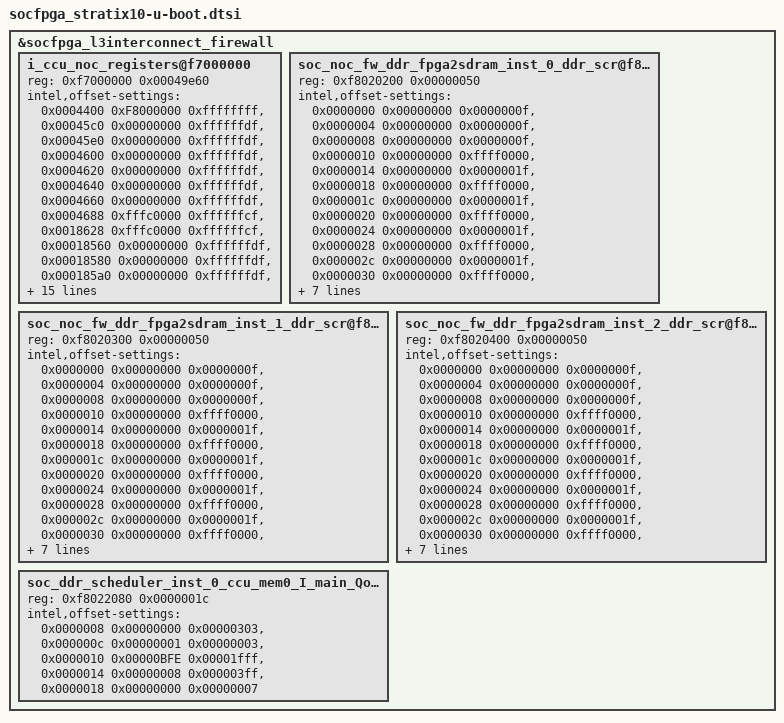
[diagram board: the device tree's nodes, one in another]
// SPDX-License-Identifier: GPL-2.0+
/*
 * U-Boot additions
 *
 * Copyright (C) 2020 Intel Corporation <www.intel.com>
 */

#include "socfpga_soc64_u-boot.dtsi"
#include "socfpga_soc64_fit-u-boot.dtsi"

&socfpga_l3interconnect_firewall {
	i_ccu_noc_registers@f7000000 {
		reg = <0xf7000000 0x00049e60>;
		intel,offset-settings =
			/* Enable access to DDR reg from CPU */
			<0x0004400 0xF8000000 0xffffffff>,

			/* Enable access to DDR region from CPU */
			<0x00045c0 0x00000000 0xffffffdf>,
			<0x00045e0 0x00000000 0xffffffdf>,
			<0x0004600 0x00000000 0xffffffdf>,
			<0x0004620 0x00000000 0xffffffdf>,
			<0x0004640 0x00000000 0xffffffdf>,
			<0x0004660 0x00000000 0xffffffdf>,

			/* Disable ocram security at CCU for non secure access */
			<0x0004688 0xfffc0000 0xffffffcf>,
			<0x0018628 0xfffc0000 0xffffffcf>,

			/* Enable access to DDR region from IO master */
			<0x00018560 0x00000000 0xffffffdf>,
			<0x00018580 0x00000000 0xffffffdf>,
			<0x000185a0 0x00000000 0xffffffdf>,
			<0x000185c0 0x00000000 0xffffffdf>,
			<0x000185e0 0x00000000 0xffffffdf>,
			<0x00018600 0x00000000 0xffffffdf>,

			/* Enable access to DDR region from TCU */
			<0x0002c520 0x00000000 0xffffffdf>,
			<0x0002c540 0x00000000 0xffffffdf>,
			<0x0002c560 0x00000000 0xffffffdf>,
			<0x0002c580 0x00000000 0xffffffdf>,
			<0x0002c5a0 0x00000000 0xffffffdf>,
			<0x0002c5c0 0x00000000 0xffffffdf>,

			/* Enable access to DDR region from FPGA */
			<0x000105a0 0x00000000 0xffffffdf>,
			<0x000105c0 0x00000000 0xffffffdf>,
			<0x000105e0 0x00000000 0xffffffdf>,
			<0x00010600 0x00000000 0xffffffdf>,
			<0x00010620 0x00000000 0xffffffdf>,
			<0x00010640 0x00000000 0xffffffdf>;
		bootph-all;
	};

	/*
	 * Both firewall and QOS regs accessed by CPU in MPFE has
	 * dependency on CCU configuration above.
	 *
	 * Below are all fpga2sdram firewall settings with default
	 * reset value for the sake of easy reference by users.
	 * Users may choose to remove any of these register configurations
	 * that they do not require in their specific implementation.
	 */
	soc_noc_fw_ddr_fpga2sdram_inst_0_ddr_scr@f8020200 {
		reg = <0xf8020200 0x00000050>;
		intel,offset-settings =
			<0x0000000 0x00000000 0x0000000f>,
			<0x0000004 0x00000000 0x0000000f>,
			<0x0000008 0x00000000 0x0000000f>,
			<0x0000010 0x00000000 0xffff0000>,
			<0x0000014 0x00000000 0x0000001f>,
			<0x0000018 0x00000000 0xffff0000>,
			<0x000001c 0x00000000 0x0000001f>,
			<0x0000020 0x00000000 0xffff0000>,
			<0x0000024 0x00000000 0x0000001f>,
			<0x0000028 0x00000000 0xffff0000>,
			<0x000002c 0x00000000 0x0000001f>,
			<0x0000030 0x00000000 0xffff0000>,
			<0x0000034 0x00000000 0x0000001f>,
			<0x0000038 0x00000000 0xffff0000>,
			<0x000003c 0x00000000 0x0000001f>,
			<0x0000040 0x00000000 0xffff0000>,
			<0x0000044 0x00000000 0x0000001f>,
			<0x0000048 0x00000000 0xffff0000>,
			<0x000004c 0x00000000 0x0000001f>;
		bootph-all;
	};

	soc_noc_fw_ddr_fpga2sdram_inst_1_ddr_scr@f8020300 {
		reg = <0xf8020300 0x00000050>;
		intel,offset-settings =
			<0x0000000 0x00000000 0x0000000f>,
			<0x0000004 0x00000000 0x0000000f>,
			<0x0000008 0x00000000 0x0000000f>,
			<0x0000010 0x00000000 0xffff0000>,
			<0x0000014 0x00000000 0x0000001f>,
			<0x0000018 0x00000000 0xffff0000>,
			<0x000001c 0x00000000 0x0000001f>,
			<0x0000020 0x00000000 0xffff0000>,
			<0x0000024 0x00000000 0x0000001f>,
			<0x0000028 0x00000000 0xffff0000>,
			<0x000002c 0x00000000 0x0000001f>,
			<0x0000030 0x00000000 0xffff0000>,
			<0x0000034 0x00000000 0x0000001f>,
			<0x0000038 0x00000000 0xffff0000>,
			<0x000003c 0x00000000 0x0000001f>,
			<0x0000040 0x00000000 0xffff0000>,
			<0x0000044 0x00000000 0x0000001f>,
			<0x0000048 0x00000000 0xffff0000>,
			<0x000004c 0x00000000 0x0000001f>;
		bootph-all;
	};

	soc_noc_fw_ddr_fpga2sdram_inst_2_ddr_scr@f8020400 {
		reg = <0xf8020400 0x00000050>;
		intel,offset-settings =
			<0x0000000 0x00000000 0x0000000f>,
			<0x0000004 0x00000000 0x0000000f>,
			<0x0000008 0x00000000 0x0000000f>,
			<0x0000010 0x00000000 0xffff0000>,
			<0x0000014 0x00000000 0x0000001f>,
			<0x0000018 0x00000000 0xffff0000>,
			<0x000001c 0x00000000 0x0000001f>,
			<0x0000020 0x00000000 0xffff0000>,
			<0x0000024 0x00000000 0x0000001f>,
			<0x0000028 0x00000000 0xffff0000>,
			<0x000002c 0x00000000 0x0000001f>,
			<0x0000030 0x00000000 0xffff0000>,
			<0x0000034 0x00000000 0x0000001f>,
			<0x0000038 0x00000000 0xffff0000>,
			<0x000003c 0x00000000 0x0000001f>,
			<0x0000040 0x00000000 0xffff0000>,
			<0x0000044 0x00000000 0x0000001f>,
			<0x0000048 0x00000000 0xffff0000>,
			<0x000004c 0x00000000 0x0000001f>;
		bootph-all;
	};

	/*
	 * Example of ccu_mem0_I_main QOS settings with
	 * default reset value for the sake of easy reference
	 * by users. Users may choose to remove any of these register
	 * configurations that they do not require in their specific
	 * implementation.
	 */
	soc_ddr_scheduler_inst_0_ccu_mem0_I_main_QosGenerator@f8022080 {
		reg = <0xf8022080 0x0000001c>;
		intel,offset-settings =
			<0x0000008 0x00000000 0x00000303>,
			<0x000000c 0x00000001 0x00000003>,
			<0x0000010 0x00000BFE 0x00001fff>,
			<0x0000014 0x00000008 0x000003ff>,
			<0x0000018 0x00000000 0x00000007>;
		bootph-all;
	};
};
